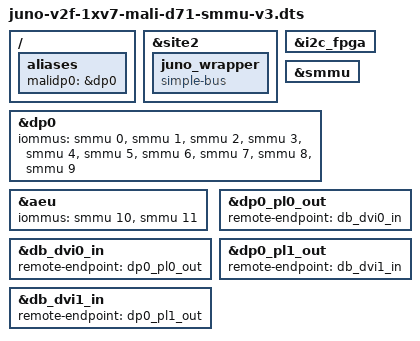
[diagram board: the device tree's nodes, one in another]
/*
 * ARM Juno development platform with single Virtex 7 logic tile
 * and HDMI daughterboard.
 * Configured for a bitfile containing a Mali-D71.
 */

#include "juno-r1.dts"

/ {
	aliases {
		malidp0 = &dp0;
	};
};

&site2 {
	juno_wrapper {
		compatible = "simple-bus";
		#address-cells = <1>;
		#size-cells = <1>;
		/*
		 * The mapping on Juno is rather complicated.
		 * The lowest slaves: 0-0x0009ffff are mapped to 0x6f100000 (physical)
		 * The "mid" slaves:  0x00200000-0x00ffffff are mapped to 0x6f200000 (physical)
		 * The "high" slaves: 0x0c000000-0x0c09ffff are mapped to 0x6f000000 (physical)
		 */
		ranges = <0          0x0f100000 0x0a0000>,
			 <0x00200000 0x0f200000 0xe00000>,
			 <0x0c000000 0x0f000000 0x0a0000>;

		/include/ "v2f-1xv7-malidp-framework.dtsi"
		/include/ "v2f-1xv7-malidp-d71.dtsi"
	};
};

&i2c_fpga {
	status = "okay";
	/include/ "v2c-hdmi.dtsi"
};

&smmu {
	status = "okay";
	#iommu-cells = <1>;
};

/* Configure DP0 with daughterboard transmitters */
&dp0 {
	iommus = <&smmu 0>, <&smmu 1>, <&smmu 2>, <&smmu 3>,
		 <&smmu 4>, <&smmu 5>, <&smmu 6>, <&smmu 7>,
		 <&smmu 8>, <&smmu 9>;
	status = "okay";
};

&aeu {
	iommus = <&smmu 10>, <&smmu 11>;
	status = "okay";
};

&db_dvi0_in {
	remote-endpoint = <&dp0_pl0_out>;
};

&db_dvi1_in {
	remote-endpoint = <&dp0_pl1_out>;
};

&dp0_pl0_out {
	remote-endpoint = <&db_dvi0_in>;
};

&dp0_pl1_out {
	remote-endpoint = <&db_dvi1_in>;
};
